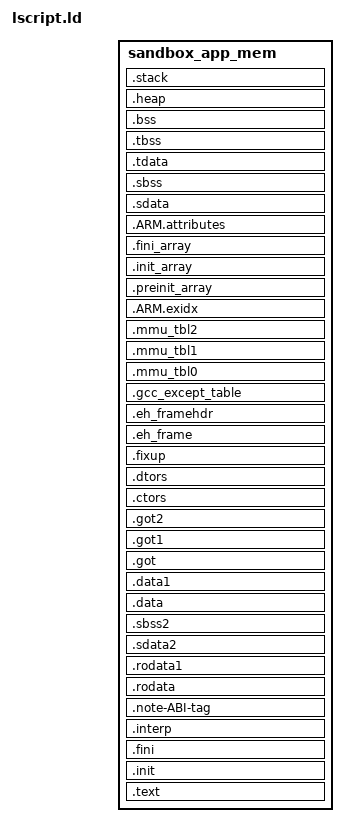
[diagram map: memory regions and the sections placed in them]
/*////////////////////////////////////////////////////////////////////////////////////////////////////////////////////////////
// (C) Copyright 2023 ABB. All rights reserved.
//////////////////////////////////////////////////////////////////////////////////////////////////////////////////////////////
// Description: Linker command file for building sandbox application
////////////////////////////////////////////////////////////////////////////////////////////////////////////////////////////*/

_STACK_SIZE = 0x10000;
_HEAP_SIZE  = 0x10000;

/* Include virtual memory location and length definitions */
INCLUDE  sandbox-sdk/application_api/aarch64/sandbox_virtmem_definitions.lcf


MEMORY
{
    sandbox_app_mem         : ORIGIN = _SANDBOX_VIRT_ORIGIN,  LENGTH = _SANDBOX_VIRT_LENGTH
}

/* Specify the default entry point to the program */

ENTRY(_startup)

/* Define the sections, and where they are mapped in memory */

SECTIONS
{
.text : {
   KEEP (*(.vectors))
   *(.boot)
   *(.text)
   *(.text.*)
   *(.gnu.linkonce.t.*)
   *(.plt)
   *(.gnu_warning)
   *(.gcc_execpt_table)
   *(.glue_7)
   *(.glue_7t)
   *(.ARM.extab)
   *(.gnu.linkonce.armextab.*)
} > sandbox_app_mem

.init ALIGN(64) : {
   KEEP (*(.init))
} > sandbox_app_mem

.fini ALIGN(64) : {
   KEEP (*(.fini))
} > sandbox_app_mem

.interp : {
   KEEP (*(.interp))
} > sandbox_app_mem

.note-ABI-tag : {
   KEEP (*(.note-ABI-tag))
} > sandbox_app_mem

.rodata ALIGN(64) : {
   __rodata_start = .;
   *(.rodata)
   *(.rodata.*)
   *(.gnu.linkonce.r.*)
   __rodata_end = .;
} > sandbox_app_mem

.rodata1 : {
   . = ALIGN(64);
   __rodata1_start = .;
   *(.rodata1)
   *(.rodata1.*)
   __rodata1_end = .;
} > sandbox_app_mem

.sdata2 : {
   . = ALIGN(64);
   __sdata2_start = .;
   *(.sdata2)
   *(.sdata2.*)
   *(.gnu.linkonce.s2.*)
   __sdata2_end = .;
} > sandbox_app_mem

.sbss2 : {
   . = ALIGN(64);
   __sbss2_start = .;
   *(.sbss2)
   *(.sbss2.*)
   *(.gnu.linkonce.sb2.*)
   __sbss2_end = .;
} > sandbox_app_mem

.data : {
   . = ALIGN(64);
   __data_start = .;
   *(.data)
   *(.data.*)
   *(.gnu.linkonce.d.*)
   *(.jcr)
   *(.got)
   *(.got.plt)
   __data_end = .;
} > sandbox_app_mem

.data1 : {
   . = ALIGN(64);
   __data1_start = .;
   *(.data1)
   *(.data1.*)
   __data1_end = .;
} > sandbox_app_mem

.got : {
   *(.got)
} > sandbox_app_mem

.got1 : {
   *(.got1)
} > sandbox_app_mem

.got2 : {
   *(.got2)
} > sandbox_app_mem

.ctors : {
   . = ALIGN(64);
   __CTOR_LIST__ = .;
   ___CTORS_LIST___ = .;
   KEEP (*crtbegin.o(.ctors))
   KEEP (*(EXCLUDE_FILE(*crtend.o) .ctors))
   KEEP (*(SORT(.ctors.*)))
   KEEP (*(.ctors))
   __CTOR_END__ = .;
   ___CTORS_END___ = .;
} > sandbox_app_mem

.dtors : {
   . = ALIGN(64);
   __DTOR_LIST__ = .;
   ___DTORS_LIST___ = .;
   KEEP (*crtbegin.o(.dtors))
   KEEP (*(EXCLUDE_FILE(*crtend.o) .dtors))
   KEEP (*(SORT(.dtors.*)))
   KEEP (*(.dtors))
   __DTOR_END__ = .;
   ___DTORS_END___ = .;
} > sandbox_app_mem

.fixup : {
   __fixup_start = .;
   *(.fixup)
   __fixup_end = .;
} > sandbox_app_mem

.eh_frame : {
   *(.eh_frame)
} > sandbox_app_mem

.eh_framehdr : {
   __eh_framehdr_start = .;
   *(.eh_framehdr)
   __eh_framehdr_end = .;
} > sandbox_app_mem

.gcc_except_table : {
    . = ALIGN(64);
    *(.gcc_except_table)
    *(.gcc_except_table*) ;
    . = ALIGN(64);
  } > sandbox_app_mem

.mmu_tbl0 (ALIGN(4096)) : {
   __mmu_tbl0_start = .;
   *(.mmu_tbl0)
   __mmu_tbl0_end = .;
} > sandbox_app_mem

.mmu_tbl1 (ALIGN(4096)) : {
   __mmu_tbl1_start = .;
   *(.mmu_tbl1)
   __mmu_tbl1_end = .;
} > sandbox_app_mem

.mmu_tbl2 (ALIGN(4096)) : {
   __mmu_tbl2_start = .;
   *(.mmu_tbl2)
   __mmu_tbl2_end = .;
} > sandbox_app_mem

.ARM.exidx : {
   __exidx_start = .;
   *(.ARM.exidx*)
   *(.gnu.linkonce.armexidix.*.*)
   __exidx_end = .;
} > sandbox_app_mem

.preinit_array : {
   . = ALIGN(64);
   __preinit_array_start = .;
   KEEP (*(SORT(.preinit_array.*)))
   KEEP (*(.preinit_array))
   __preinit_array_end = .;
} > sandbox_app_mem

.init_array : {
   . = ALIGN(64);
   __init_array_start = .;
   KEEP (*(SORT(.init_array.*)))
   KEEP (*(.init_array))
   __init_array_end = .;
} > sandbox_app_mem

.fini_array : {
   . = ALIGN(64);
   __fini_array_start = .;
   KEEP (*(SORT(.fini_array.*)))
   KEEP (*(.fini_array))
   __fini_array_end = .;
} > sandbox_app_mem

.ARM.attributes : {
   __ARM.attributes_start = .;
   *(.ARM.attributes)
   __ARM.attributes_end = .;
} > sandbox_app_mem

.sdata : {
   . = ALIGN(64);
   __sdata_start = .;
   *(.sdata)
   *(.sdata.*)
   *(.gnu.linkonce.s.*)
   __sdata_end = .;
} > sandbox_app_mem

.sbss (NOLOAD) : {
   . = ALIGN(64);
   __sbss_start = .;
   *(.sbss)
   *(.sbss.*)
   *(.gnu.linkonce.sb.*)
   . = ALIGN(64);
   __sbss_end = .;
} > sandbox_app_mem

.tdata : {
   . = ALIGN(64);
   __tdata_start = .;
   *(.tdata)
   *(.tdata.*)
   *(.gnu.linkonce.td.*)
   __tdata_end = .;
} > sandbox_app_mem

.tbss : {
   . = ALIGN(64);
   __tbss_start = .;
   *(.tbss)
   *(.tbss.*)
   *(.gnu.linkonce.tb.*)
   __tbss_end = .;
} > sandbox_app_mem

.bss (NOLOAD) : {
   . = ALIGN(64);
   __bss_start__ = .;
   *(.bss)
   *(.bss.*)
   *(.gnu.linkonce.b.*)
   *(COMMON)
   . = ALIGN(64);
   __bss_end__ = .;
} > sandbox_app_mem

_SDA_BASE_ = __sdata_start + ((__sbss_end - __sdata_start) / 2 );

_SDA2_BASE_ = __sdata2_start + ((__sbss2_end - __sdata2_start) / 2 );

/* Generate Stack and Heap definitions */

.heap (NOLOAD) : {
   . = ALIGN(64);
   _heap = .;
   HeapBase = .;
   _heap_start = .;
   . += _HEAP_SIZE;
   _heap_end = .;
   HeapLimit = .;
} > sandbox_app_mem

_end = .;

.stack (NOLOAD) : {
   _stack_lower = .;
   . += _STACK_SIZE;
   . = ALIGN(64);
   _stack_upper = .;
} > sandbox_app_mem

}
